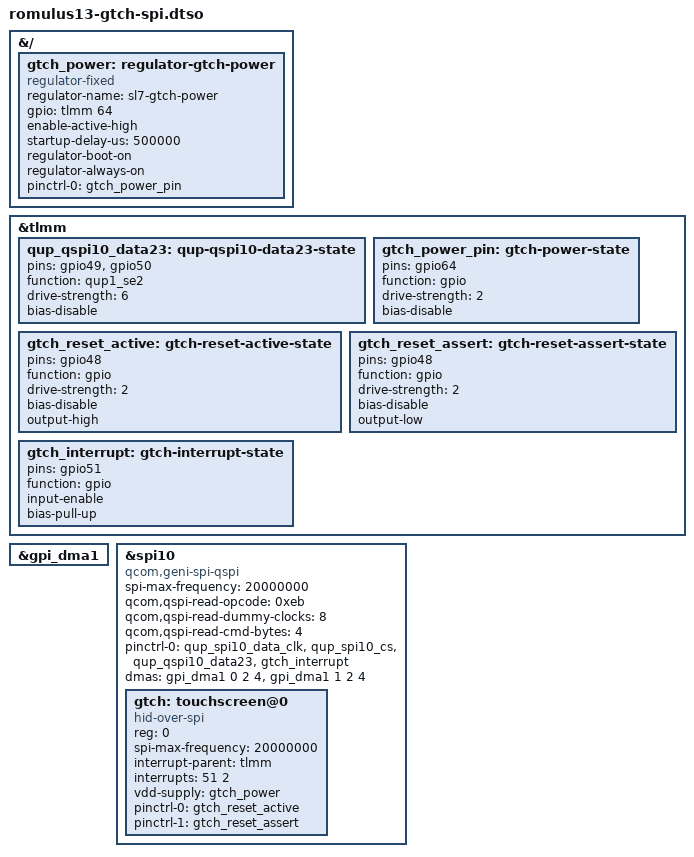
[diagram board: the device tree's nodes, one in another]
// SPDX-License-Identifier: BSD-3-Clause
/*
 * Trial: GTCH (HID-over-SPI) touchscreen on spi10 for 13.8-inch Surface Laptop 7
 * units without the I2C ITCH panel. Wiring from this machine's SSDT GTCH device
 * (SP11, GpioInt 51, GpioIo 64) and the CouchLiteOS/romulus15 GTCH description:
 * https://github.com/Dudiebug/couchliteos/blob/arm64-sl7/kernel/sl7/patches/0003-romulus15-gtch-spi-touchscreen.patch
 */
/dts-v1/;
/plugin/;

&{/} {
	gtch_power: regulator-gtch-power {
		compatible = "regulator-fixed";
		regulator-name = "sl7-gtch-power";
		gpio = <&tlmm 64 0>;
		enable-active-high;
		startup-delay-us = <500000>;
		regulator-boot-on;
		regulator-always-on;
		pinctrl-names = "default";
		pinctrl-0 = <&gtch_power_pin>;
	};
};

&tlmm {
	qup_qspi10_data23: qup-qspi10-data23-state {
		pins = "gpio49", "gpio50";
		function = "qup1_se2";
		drive-strength = <6>;
		bias-disable;
	};
	gtch_power_pin: gtch-power-state {
		pins = "gpio64";
		function = "gpio";
		drive-strength = <2>;
		bias-disable;
	};
	gtch_reset_active: gtch-reset-active-state {
		pins = "gpio48";
		function = "gpio";
		drive-strength = <2>;
		bias-disable;
		output-high;
	};
	gtch_reset_assert: gtch-reset-assert-state {
		pins = "gpio48";
		function = "gpio";
		drive-strength = <2>;
		bias-disable;
		output-low;
	};
	gtch_interrupt: gtch-interrupt-state {
		pins = "gpio51";
		function = "gpio";
		input-enable;
		bias-pull-up;
	};
};

&gpi_dma1 {
	status = "okay";
};

&spi10 {
	compatible = "qcom,geni-spi-qspi";
	spi-max-frequency = <20000000>;
	qcom,qspi-read-opcode = <0xeb>;
	qcom,qspi-read-dummy-clocks = <8>;
	qcom,qspi-read-cmd-bytes = <4>;
	pinctrl-0 = <&qup_spi10_data_clk>, <&qup_spi10_cs>, <&qup_qspi10_data23>, <&gtch_interrupt>;
	pinctrl-names = "default";
	dmas = <&gpi_dma1 0 2 4>, <&gpi_dma1 1 2 4>;
	dma-names = "tx", "rx";
	#address-cells = <1>;
	#size-cells = <0>;
	status = "okay";

	gtch: touchscreen@0 {
		compatible = "hid-over-spi";
		reg = <0>;
		spi-max-frequency = <20000000>;
		interrupt-parent = <&tlmm>;
		interrupts = <51 2>;
		vdd-supply = <&gtch_power>;
		pinctrl-0 = <&gtch_reset_active>;
		pinctrl-1 = <&gtch_reset_assert>;
		pinctrl-names = "active", "reset";
	};
};
